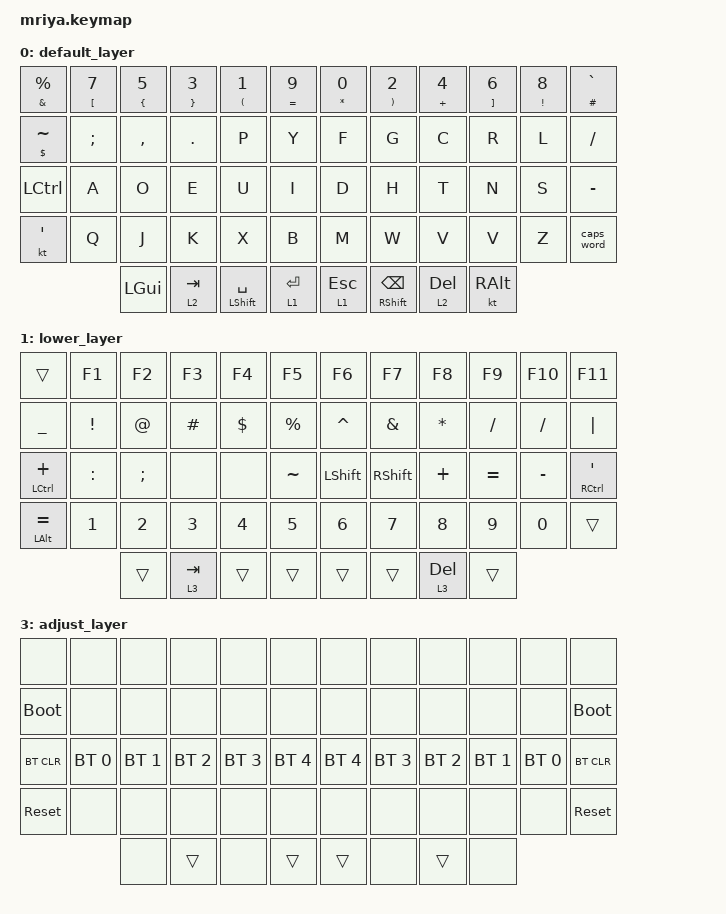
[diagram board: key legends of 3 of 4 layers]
/*
 * Copyright (c) 2023 Andrei Gaevskii
 *
 * SPDX-License-Identifier: MIT
 */

#include <behaviors.dtsi>
#include <dt-bindings/zmk/bt.h>
#include <dt-bindings/zmk/keys.h>
#include <dt-bindings/zmk/keys.h>

#define DEF 0
#define LWR 1
#define RSE 2
#define ADJ 3

&lt { quick_tap_ms = <200>; };

&mt { quick_tap_ms = <200>; };

/ {
    keymap {
        compatible = "zmk,keymap";

        default_layer {
            bindings = <
  &mt AMPERSAND PERCENT  &mt LEFT_BRACKET N7  &mt LEFT_BRACE N5  &mt RIGHT_BRACE NUMBER_3  &mt LEFT_PARENTHESIS NUMBER_1  &mt EQUAL N9    &mt ASTERISK N0  &mt RIGHT_PARENTHESIS NUMBER_2  &mt PLUS NUMBER_4  &mt RIGHT_BRACKET NUMBER_6  &mt EXCLAMATION N8  &mt HASH GRAVE
  &mt DOLLAR TILDE       &kp SEMI             &kp COMMA          &kp PERIOD                &kp P                          &kp Y           &kp F            &kp G                           &kp C              &kp R                       &kp L               &kp SLASH
  &kp LCTRL              &kp A                &kp O              &kp E                     &kp U                          &kp I           &kp D            &kp H                           &kp T              &kp N                       &kp S               &kp MINUS
  &kt SQT                &kp Q                &kp J              &kp K                     &kp X                          &kp B           &kp M            &kp W                           &kp V              &kp V                       &kp Z               &caps_word
                                              &kp LGUI           &lt 2 TAB                 &mt LSHFT SPACE                &lt 1 RET       &lt 1 ESC        &mt RSHFT BSPC                  &lt 2 DEL          &kt RIGHT_ALT
            >;
        };

        lower_layer {
            bindings = <
  &trans          &kp F1     &kp F2    &kp F3     &kp F4    &kp F5       &kp F6      &kp F7      &kp F8     &kp F9     &kp F10    &kp F11
  &kp UNDERSCORE  &kp EXCL   &kp AT    &kp HASH   &kp DLLR  &kp PRCNT    &kp CARET   &kp AMPS    &kp STAR   &kp SLASH  &kp SLASH  &kp PIPE
  &mt LCTRL PLUS  &kp COLON  &kp SEMI  &none      &none     &kp TILDE    &kp LSHIFT  &kp RSHIFT  &kp PLUS   &kp EQUAL  &kp MINUS  &mt RCTRL SQT
  &mt LALT EQUAL  &kp N1     &kp N2    &kp N3     &kp N4    &kp N5       &kp N6      &kp N7      &kp N8     &kp N9     &kp N0     &trans
                             &trans    &lt 3 TAB  &trans    &trans       &trans      &trans      &lt 3 DEL  &trans
            >;
        };

        raise_layer {
            bindings = <
  &trans           &kp STAR      &kp KP_N7        &kp KP_N8  &kp KP_N9  &kp KP_MINUS    &kp C_VOL_UP  &kp HOME  &kp PSCRN  &kp PG_UP  &kp SLCK         &kp CAPS
  &kp KP_NUM       &kp KP_SLASH  &kp KP_MULTIPLY  &kp KP_N5  &kp KP_N6  &kp KP_PLUS     &kp C_MUTE    &kp LEFT  &kp UP     &kp RIGHT  &kp INS          &mt RCTRL K_APP
  &mt LCTRL EQUAL  &kp KP_N4     &kp KP_N1        &kp KP_N2  &kp KP_N3  &kp KP_DOT      &kp C_VOL_DN  &kp END   &kp DOWN   &kp PG_DN  &kp PAUSE_BREAK  &trans
  &trans           &trans        &trans           &lt 3 RET  &lt 3 ESC  &trans          &trans        &trans
            >;
        };

        adjust_layer {
            bindings = <
  &none        &none         &none         &none         &none         &none           &none         &none         &none         &none         &none         &none
  &bootloader  &none         &none         &none         &none         &none           &none         &none         &none         &none         &none         &bootloader
  &bt BT_CLR   &bt BT_SEL 0  &bt BT_SEL 1  &bt BT_SEL 2  &bt BT_SEL 3  &bt BT_SEL 4    &bt BT_SEL 4  &bt BT_SEL 3  &bt BT_SEL 2  &bt BT_SEL 1  &bt BT_SEL 0  &bt BT_CLR
  &sys_reset   &none         &none         &none         &none         &none           &none         &none         &none         &none         &none         &sys_reset
                             &none         &trans        &none         &trans          &trans        &none         &trans        &none
            >;
        };
    };
};
